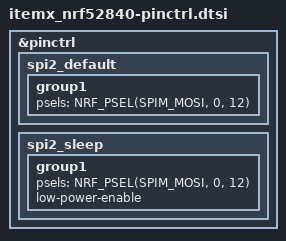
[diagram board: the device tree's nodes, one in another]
/*
 * SPDX-License-Identifier: Apache-2.0
 *
 * Pin control for ITEMX board (nRF52840)
 * SPI2 is used to drive the SK6812 LED strip via MOSI on P0.12
 */

&pinctrl {
	spi2_default: spi2_default {
		group1 {
			psels = <NRF_PSEL(SPIM_MOSI, 0, 12)>;
		};
	};

	spi2_sleep: spi2_sleep {
		group1 {
			psels = <NRF_PSEL(SPIM_MOSI, 0, 12)>;
			low-power-enable;
		};
	};
};
